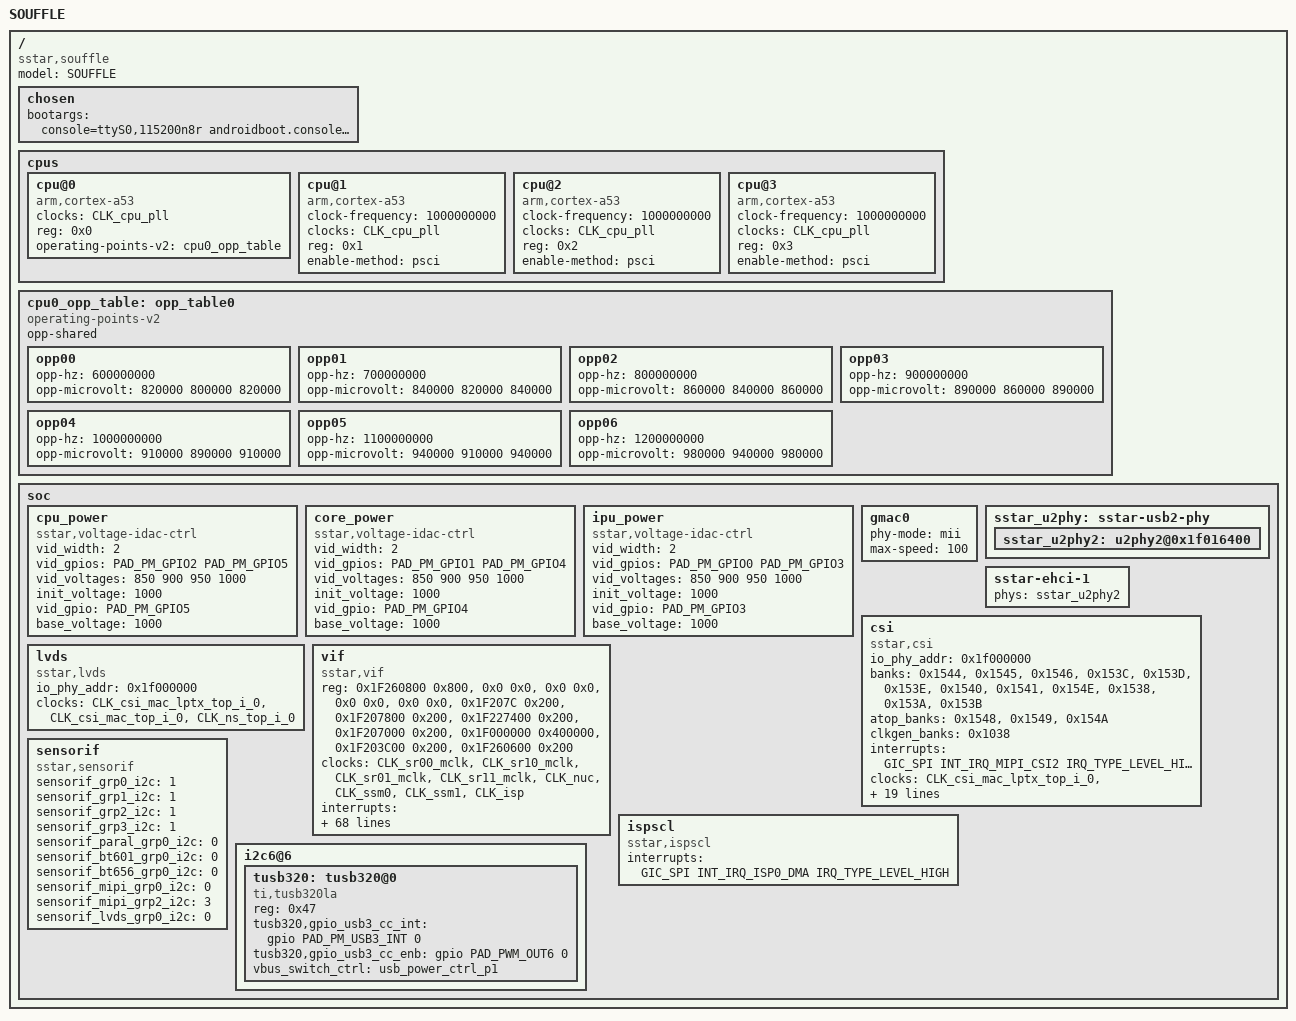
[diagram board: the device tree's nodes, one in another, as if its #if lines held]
/*
* souffle-ssm000c-s01a-usbcam.dts- Sigmastar
*
* Copyright (c) [2019~2020] SigmaStar Technology.
*
*
* This software is licensed under the terms of the GNU General Public
* License version 2, as published by the Free Software Foundation, and
* may be copied, distributed, and modified under those terms.
*
* This program is distributed in the hope that it will be useful,
* but WITHOUT ANY WARRANTY; without even the implied warranty of
* MERCHANTABILITY or FITNESS FOR A PARTICULAR PURPOSE.  See the
* GNU General Public License version 2 for more details.
*
*/

/dts-v1/;
#include "souffle.dtsi"
#include "souffle-camdriver.dtsi"
#include "souffle-ssm000c-s01a-usbcam-padmux.dtsi"

/ {
    #address-cells = <2>;
    #size-cells = <1>;
    model = "SOUFFLE";
    compatible = "sstar,souffle";

    chosen {
        bootargs = "console=ttyS0,115200n8r androidboot.console=ttyS0 user_debug=31 root=/dev/mtdblock0 rootfstype=squashfs ro init=/linuxrc LX_MEM=0x40000000 mma_heap=mma_heap_name0,miu=0,sz=0x20000000 mma_memblock_remove=1 cma=2M nohz=off earlyprintk";
    };

    cpus {
        #address-cells = <1>;
        #size-cells = <0>;

        cpu@0 {
            device_type = "cpu";
            compatible = "arm,cortex-a53";
            clocks = <&CLK_cpu_pll>;
            reg = <0x0>;
            operating-points-v2 = <&cpu0_opp_table>;
        };

#ifdef CONFIG_SMP
        cpu@1 {
            device_type = "cpu";
            compatible = "arm,cortex-a53";
            clock-frequency = <1000000000>;
            clocks = <&CLK_cpu_pll>;
            reg = <0x1>;
#if CONFIG_ENABLE_METHOD_PSCI
            enable-method = "psci";
#endif
        };

        cpu@2 {
            device_type = "cpu";
            compatible = "arm,cortex-a53";
            clock-frequency = <1000000000>;
            clocks = <&CLK_cpu_pll>;
            reg = <0x2>;
#if CONFIG_ENABLE_METHOD_PSCI
            enable-method = "psci";
#endif
        };

        cpu@3 {
            device_type = "cpu";
            compatible = "arm,cortex-a53";
            clock-frequency = <1000000000>;
            clocks = <&CLK_cpu_pll>;
            reg = <0x3>;
#if CONFIG_ENABLE_METHOD_PSCI
            enable-method = "psci";
#endif
        };
#endif
    };

    cpu0_opp_table: opp_table0 {
        compatible = "operating-points-v2";
        opp-shared;
        opp00 {
            opp-hz = /bits/ 64 <600000000>;
            opp-microvolt = <820000 800000 820000>; /* <normal min max> */
            status = "ok";
        };

        opp01 {
            opp-hz = /bits/ 64 <700000000>;
            opp-microvolt = <840000 820000 840000>;
            status = "ok";
        };

        opp02 {
            opp-hz = /bits/ 64 <800000000>;
            opp-microvolt = <860000 840000 860000>;
            status = "ok";
        };

        opp03 {
            opp-hz = /bits/ 64 <900000000>;
            opp-microvolt = <890000 860000 890000>;
            status = "ok";
        };

        opp04 {
            opp-hz = /bits/ 64 <1000000000>;
            opp-microvolt = <910000 890000 910000>;
            status = "ok";
        };

        opp05 {
            opp-hz = /bits/ 64 <1100000000>;
            opp-microvolt = <940000 910000 940000>;
            status = "ok";
        };

        opp06 {
            opp-hz = /bits/ 64 <1200000000>;
            opp-microvolt = <980000 940000 980000>;
            status = "ok";
        };
    };

    soc {
#ifdef CONFIG_SSTAR_VOLTAGE_CTRL
        cpu_power {
            compatible = "sstar,voltage-ctrl";
            vid_width = <2>;
            vid_gpios = <PAD_PM_GPIO2 PAD_PM_GPIO5>;
            vid_voltages = <850 900 950 1000>;  //2b'00 2b'01 2b'10 2b'11
            init_voltage = <1000>;
            status = "ok";                      //ref to 1V0_STD_2 on sch
        };

        core_power {
            compatible = "sstar,voltage-ctrl";
            vid_width = <2>;
            vid_gpios = <PAD_PM_GPIO1 PAD_PM_GPIO4>;
            vid_voltages = <850 900 950 1000>;  //2b'00 2b'01 2b'10 2b'11
            init_voltage = <1000>;
            status = "ok";                      //ref to 1V0_STD on sch
        };

        ipu_power {
            compatible = "sstar,voltage-ctrl";
            vid_width = <2>;
            vid_gpios = <PAD_PM_GPIO0 PAD_PM_GPIO3>;
            vid_voltages = <850 900 950 1000>;  //2b'00 2b'01 2b'10 2b'11
            init_voltage = <1000>;
            status = "ok";                      //ref to 1V0_STD_3 on sch
        };
#endif

#ifdef CONFIG_SSTAR_VOLTAGE_IDAC_CTRL
        cpu_power {
            compatible = "sstar,voltage-idac-ctrl";
            vid_gpio = <PAD_PM_GPIO5>;
            base_voltage = <1000>;
            init_voltage = <1000>;
            status = "ok";
        };

        core_power {
            compatible = "sstar,voltage-idac-ctrl";
            vid_gpio = <PAD_PM_GPIO4>;
            base_voltage = <1000>;
            init_voltage = <1000>;
            status = "ok";
        };

        ipu_power {
            compatible = "sstar,voltage-idac-ctrl";
            vid_gpio = <PAD_PM_GPIO3>;
            base_voltage = <1000>;
            init_voltage = <1000>;
            status = "ok";
        };
#endif
        gmac0: gmac0 {
            phy-mode = "mii";
            max-speed = <100>;
        };

        sstar_u2phy: sstar-usb2-phy {
            sstar_u2phy2: u2phy2@0x1f016400 {
                status = "ok";
            };
        };

        sstar-ehci-1 {
            phys = <&sstar_u2phy2>;
        };

        csi: csi {
            compatible = "sstar,csi";
            io_phy_addr = <0x1f000000>;
            banks = <0x1544>,<0x1545>,<0x1546>,<0x153C>,<0x153D>,<0x153E>,<0x1540>,<0x1541>,<0x154E>,<0x1538>,<0x153A>,<0x153B>;
            atop_banks = <0x1548>,<0x1549>,<0x154A>;
            clkgen_banks = <0x1038>;
            interrupts=  <GIC_SPI INT_IRQ_MIPI_CSI2 IRQ_TYPE_LEVEL_HIGH>;
            clocks = <&CLK_csi_mac_lptx_top_i_0>,<&CLK_csi_mac_top_i_0>,<&CLK_ns_top_i_0>,<&CLK_csi_mac_lptx_top_i_1>,<&CLK_csi_mac_top_i_1>,<&CLK_ns_top_i_1>,<&CLK_csi_mac_lptx_top_i_2>,<&CLK_csi_mac_top_i_2>,<&CLK_ns_top_i_2>,<&CLK_csi_mac_lptx_top_i_3>,<&CLK_csi_mac_top_i_3>,<&CLK_ns_top_i_3>;
            //clocks = <&CLK_csi_mac_lptx_top_i_m00>,<&CLK_csi_mac_top_i_m00>,<&CLK_ns_top_i_m00>,<&CLK_csi_mac_lptx_top_i_m01>,<&CLK_csi_mac_top_i_m01>,<&CLK_ns_top_i_m01>;
            status = "ok";
            /* Config max lane number */
            csi_sr0_lane_num = <4>;
            csi_sr1_lane_num = <4>;
            csi_sr2_lane_num = <2>;
            csi_sr3_lane_num = <2>;
            /* Config lane selection */
            csi_sr0_lane_select = <2 1 3 0 4>;
            csi_sr1_lane_select = <2 1 3 0 4>;
            csi_sr2_lane_select = <2 1 0>;
            csi_sr3_lane_select = <2 1 0>;
            /* Config lane P/N swap */
            csi_sr0_lane_pn_swap = <0 0 0 0 0>;
            csi_sr1_lane_pn_swap = <0 0 0 0 0>;
            csi_sr2_lane_pn_swap = <0 0 0>;
            csi_sr3_lane_pn_swap = <0 0 0>;
        };

        lvds: lvds {
            compatible = "sstar,lvds";
            io_phy_addr = <0x1f000000>;
            clocks = <&CLK_csi_mac_lptx_top_i_0>,<&CLK_csi_mac_top_i_0>,<&CLK_ns_top_i_0>;
            //Attention: Sub_LVDS use the same hwirq line with the MIPI_CSI
            status = "ok";
        };

        vif: vif {
            compatible = "sstar,vif";
            status = "ok";
            reg = <0x1F260800 0x800>, <0x0 0x0>, <0x0 0x0>, <0x0 0x0>, <0x0 0x0>, <0x1F207C 0x200>, <0x1F207800 0x200>, <0x1F227400 0x200>, <0x1F207000 0x200>, <0x1F000000 0x400000>, <0x1F203C00 0x200>, <0x1F260600 0x200>;
            clocks = <&CLK_sr00_mclk>,<&CLK_sr10_mclk>,<&CLK_sr01_mclk>,<&CLK_sr11_mclk>,<&CLK_nuc>,<&CLK_ssm0>,<&CLK_ssm1>,<&CLK_isp>;
            interrupts = <GIC_SPI INT_IRQ_ISP0_VIF IRQ_TYPE_LEVEL_HIGH>;
            /* Config sensor 0 pad mux */
            vif_sr0_mipi_mode         = <1>;
            vif_sr0_mipi_ctrl_mode    = <1>;
            vif_sr0_mipi_rst_mode     = <2>;
            vif_sr0_mipi_pdn_mode     = <4>;
            vif_sr0_mipi_mclk_mode    = <2>;
            vif_sr0_mipi_mclk_id      = <0>;
            vif_sr0_par_mode          = <3>;
            vif_sr0_par_ctrl_mode     = <1>;
            vif_sr0_par_rst_mode      = <2>;
            vif_sr0_par_pdn_mode      = <4>;
            vif_sr0_par_mclk_mode     = <2>;
            vif_sr0_par_sync_mode     = <3>;
            vif_sr0_par_pclk_mode     = <3>;
            vif_sr0_par_mclk_id       = <0>;
            vif_sr0_bt656_mode        = <1>;
            vif_sr0_bt656_ctrl_mode   = <1>;
            vif_sr0_bt656_rst_mode    = <2>;
            vif_sr0_bt656_pdn_mode    = <4>;
            vif_sr0_bt656_mclk_mode   = <2>;
            vif_sr0_bt656_mclk_id     = <0>;
            vif_sr0_bt1120_mode       = <1>;
            vif_sr0_bt1120_ctrl_mode  = <1>;
            vif_sr0_bt1120_rst_mode   = <2>;
            vif_sr0_bt1120_pdn_mode   = <4>;
            vif_sr0_bt1120_mclk_mode  = <2>;
            vif_sr0_bt1120_mclk_id    = <0>;
            vif_sr0_lvds_mode         = <1>;
            vif_sr0_lvds_ctrl_mode    = <1>;
            vif_sr0_lvds_rst_mode     = <1>;
            vif_sr0_lvds_pdn_mode     = <1>;
            vif_sr0_lvds_mclk_mode    = <1>;
            vif_sr0_lvds_mclk_id      = <1>;
            vif_sr0_lvds_rst_id       = <1>;

            /* Config sensor 2 pad mux */
            vif_sr1_mipi_mode         = <1>;
            vif_sr1_mipi_ctrl_mode    = <1>;
            vif_sr1_mipi_rst_mode     = <2>;
            vif_sr1_mipi_pdn_mode     = <1>;
            vif_sr1_mipi_mclk_mode    = <1>;
            vif_sr1_mipi_mclk_id      = <1>;
            vif_sr1_par_mode          = <2>;
            vif_sr1_par_rst_mode      = <1>;
            vif_sr1_par_ctrl_mode     = <1>;
            vif_sr1_par_pdn_mode      = <1>;
            vif_sr1_par_mclk_mode     = <1>;
            vif_sr1_par_mclk_id       = <1>;
            vif_sr1_bt656_mode        = <1>;
            vif_sr1_bt656_ctrl_mode   = <1>;
            vif_sr1_bt656_rst_mode    = <1>;
            vif_sr1_bt656_pdn_mode    = <1>;
            vif_sr1_bt656_mclk_mode   = <1>;
            vif_sr1_bt656_mclk_id     = <1>;

            /* Config sensor 1 pad mux */
            vif_sr2_mipi_mode         = <1>;
            vif_sr2_mipi_ctrl_mode    = <1>;
            vif_sr2_mipi_rst_mode     = <2>;
            vif_sr2_mipi_pdn_mode     = <1>;
            vif_sr2_mipi_mclk_mode    = <2>;
            vif_sr2_mipi_mclk_id      = <2>;

            /* Config sensor 3 pad mux */
            vif_sr3_mipi_mode         = <1>;
            vif_sr3_mipi_ctrl_mode    = <2>;
            vif_sr3_mipi_rst_mode     = <1>;
            vif_sr3_mipi_pdn_mode     = <1>;
            vif_sr3_mipi_mclk_mode    = <1>;
            vif_sr3_mipi_mclk_id      = <3>;

            /*Config nuc pad mux */
            vif_nuc_isr_mclk_mode     = <2>;

            /* Config mclk 37.125MHz supported */
            vif_sr0_mclk_37p125 = <1>;
            vif_sr1_mclk_37p125 = <1>;
            vif_sr2_mclk_37p125 = <1>;
        };

        ispscl: ispscl {
            compatible = "sstar,ispscl";
            interrupts = <GIC_SPI INT_IRQ_ISP0_DMA IRQ_TYPE_LEVEL_HIGH>;
            status = "ok";
        };

        sensorif: sensorif {
            compatible = "sstar,sensorif";
            status = "ok";
            sensorif_grp0_i2c = <1>;
            sensorif_grp1_i2c = <1>;
            sensorif_grp2_i2c = <1>;
            sensorif_grp3_i2c = <1>;
            sensorif_paral_grp0_i2c = <0>;
            sensorif_bt601_grp0_i2c = <0>;
            sensorif_bt656_grp0_i2c = <0>;
            sensorif_mipi_grp0_i2c = <0>;
            sensorif_mipi_grp2_i2c = <3>;
            sensorif_lvds_grp0_i2c = <0>;
        };

        i2c6@6{
            tusb320: tusb320@0 {
                compatible = "ti,tusb320la";
                reg = <0x47>;
                tusb320,gpio_usb3_cc_int = <&gpio PAD_PM_USB3_INT 0>;
                tusb320,gpio_usb3_cc_enb = <&gpio PAD_PWM_OUT6 0>;
                vbus_switch_ctrl = <&usb_power_ctrl_p1>;
                status = "ok";
            };
        };
    };
};
